# 3065PNPIRA register map
File version: 1.0
Registers are 32-bit, access per field, reset 0x0 unless marked. A register's access mark holds for its fields unless they carry their own. Offsets are from the block's base; [hi:lo] are bit positions; {n}, {i} and the like mark numbered series.

## SYSCTRL1 — SYSCTRL1 peripheral interface
Base 0x10100000
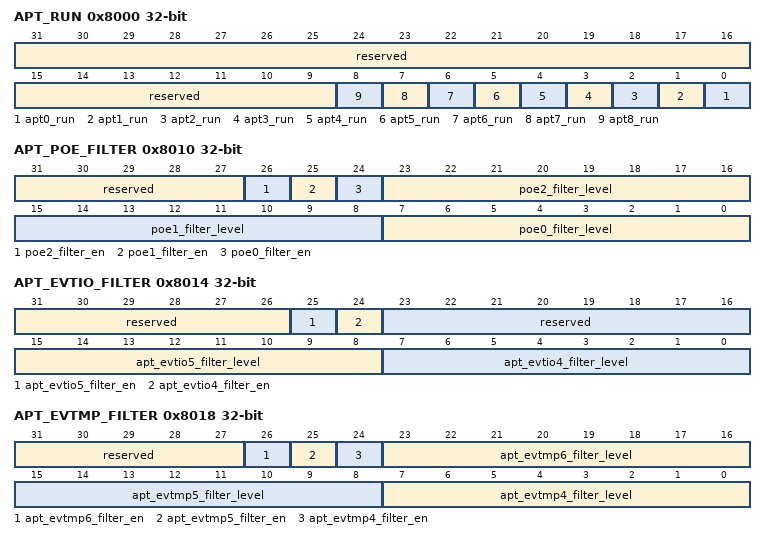
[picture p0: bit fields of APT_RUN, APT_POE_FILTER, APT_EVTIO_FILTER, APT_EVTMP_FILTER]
0x8000 APT_RUN — APT_RUN为APT使能控制寄存器。
  [31:9] reserved ro — 保留。
  [n] apt{n}_run rw (n=0..8) — APT{n}使能。 0：不使能； 1：使能。
0x8010 APT_POE_FILTER — APT_POE_FILTER为APT POE滤波控制寄存器。
  [31:27] reserved ro — 保留。
  [26] poe2_filter_en rw — POE2 FILTER使能。 0：不使能； 1：使能。
  [25] poe1_filter_en rw — POE1 FILTER使能。 0：不使能； 1：使能。
  [24] poe0_filter_en rw — POE0 FILTER使能。 0：不使能； 1：使能。
  [23:16] poe2_filter_level rw — POE2 FILTER周期数（系统总线时钟）。
  [15:8] poe1_filter_level rw — POE1 FILTER周期数（系统总线时钟）。
  [7:0] poe0_filter_level rw — POE0 FILTER周期数（系统总线时钟）。
0x8014 APT_EVTIO_FILTER — APT_EVTIO_FILTER为APT EVTIO滤波控制寄存器。
  [31:26] reserved ro — 保留。
  [25] apt_evtio5_filter_en rw — APT EVTIO5 FILTER使能。 0：不使能； 1：使能。
  [24] apt_evtio4_filter_en rw — APT EVTIO4 FILTER使能。 0：不使能； 1：使能。
  [23:16] reserved ro — 保留。
  [15:8] apt_evtio5_filter_level rw — APT EVTIO5 FILTER周期数（系统总线时钟）。
  [7:0] apt_evtio4_filter_level rw — APT EVTIO4 FILTER周期数（系统总线时钟）。
0x8018 APT_EVTMP_FILTER — APT_EVTMP_FILTER为APT EVTMP滤波控制寄存器。
  [31:27] reserved ro — 保留。
  [26] apt_evtmp6_filter_en rw — APT EVTMP6 FILTER使能。 0：不使能； 1：使能。
  [25] apt_evtmp5_filter_en rw — APT EVTMP5 FILTER使能。 0：不使能； 1：使能。
  [24] apt_evtmp4_filter_en rw — APT EVTMP4 FILTER使能。 0：不使能； 1：使能。
  [23:16] apt_evtmp6_filter_level rw — APT EVTMP6 FILTER周期数（系统总线时钟）。
  [15:8] apt_evtmp5_filter_level rw — APT EVTMP5 FILTER周期数（系统总线时钟）。
  [7:0] apt_evtmp4_filter_level rw — APT EVTMP4 FILTER周期数（系统总线时钟）。
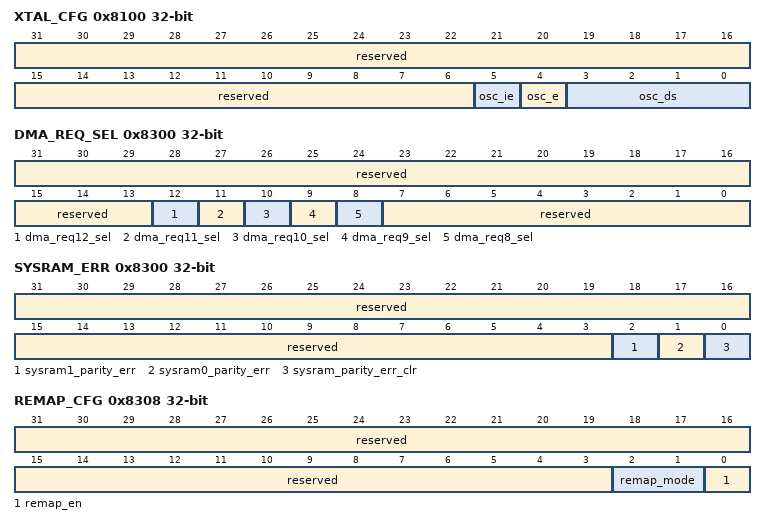
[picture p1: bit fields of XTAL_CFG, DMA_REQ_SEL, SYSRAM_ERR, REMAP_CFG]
0x8100 XTAL_CFG — XTAL_CFG为晶体IO控制寄存器。
  [31:6] reserved ro — 保留。
  [5] osc_ie rw — 晶体IO时钟输入使能。 0：不使能； 1：使能。
  [4] osc_e rw — 晶体IO谐振buf使能。 0：不使能； 1：使能。
  [3:0] osc_ds rw — 晶体IO驱动能力配置。 配置值越大，驱动能力越大。
0x8300 DMA_REQ_SEL — DMA_REQ_SEL为DMA请求线源选择寄存器。
  [31:13] reserved ro — 保留。
  [12] dma_req12_sel rw — DMA请求线12源选择。 0：CAPM0； 1：ADC2。
  [11] dma_req11_sel rw — DMA请求线11源选择。 0：SPI1_TX； 1：UART4_TX。
  [10] dma_req10_sel rw — DMA请求线10源选择。 0：SPI1_RX； 1：UART4_RX。
  [9] dma_req9_sel rw — DMA请求线9源选择。 0：SPI0_TX； 1：UART3_TX。
  [8] dma_req8_sel rw — DMA请求线8源选择。 0：SPI0_RX； 1：UART3_RX。
  [7:0] reserved ro — 保留。
0x8300 SYSRAM_ERR — SYSRAM_ERR为SYSRAM奇偶校验状态寄存器。
  [31:3] reserved ro — 保留。
  [2] sysram1_parity_err ro — SYSRAM奇偶校验错误状态。 0：无错误； 1：有错误。
  [1] sysram0_parity_err ro — SYSRAM奇偶校验错误状态。 0：无错误； 1：有错误。
  [0] sysram_parity_err_clr wo — SYSRAM奇偶校验错误状态清除。 向该位域执行写动作，会清除SYSRAM奇偶校验错误状态。
0x8308 REMAP_CFG — REMAP_CFG为系统地址空间重映射配置寄存器。 该寄存器受写保护控制，由寄存器SC_LOCKEN[sc_cfg_lock]决定。只有写使能时，对此寄存器的写操作才有效。
  [31:3] reserved ro — 保留。
  [2:1] remap_mode rw — 系统地址空间重映射模式。 00：4KB交换。系统访问0x0300_0000～0x0300_0FFF映射到FLASH main区域地址0x0300_1000~0x300_1FFF，系统访问0x0300_1000~0x0300_1FFF映射到FLASH main区域地址0x0300_0000~0x300_0FFF； 01：8KB交换。系统访问0x0300_0000~0x0300_1FFF映射到FLASH main区域地址0x0300_1000~0x300_3FFF，系统访问0x0300_1000~0x0300_3FFF映射到FLASH main区域地址0x0300_0000~0x300_1FFF； 10：128KB交换。系统访问0x0300_0000~0x0301_FFFF映射到FLASH main区域地址0x0302_0000~0x303_FFFF，系统访问0x0302_0000~0x0303_FFFF映射到FLASH main区域地址0x0300_0000~0x301_FFFF； 11：256KB交换。系统访问0x0300_0000~0x0303_FFFF映射到FLASH main区域地址0x0304_0000~0x307_FFFF，系统访问0x0304_0000~0x0307_FFFF映射到FLASH main区域地址0x0300_0000~0x303_FFFF的。
  [0] remap_en rw — 系统地址空间重映射使能。 0：不使能； 1：使能。 请先配置REMAP_CFG[remap_mode]，再配置remap_en使能地址重映射，在使能后紧随4条FENCE指令，以清空CPU流水线，完成地址重映射。
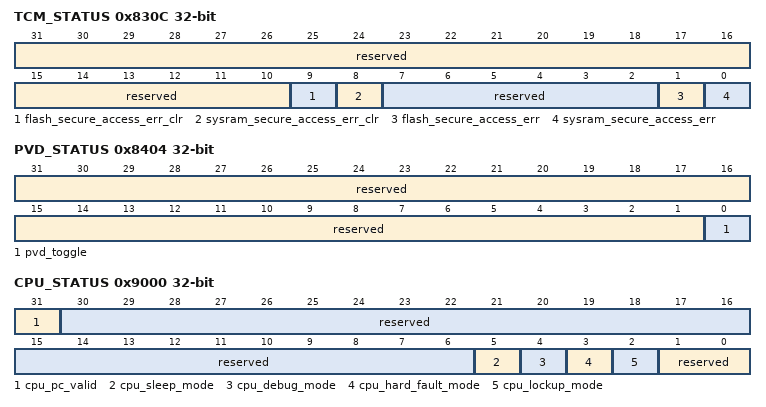
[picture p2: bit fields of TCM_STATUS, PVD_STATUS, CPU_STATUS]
0x830C TCM_STATUS — TCM_STATUS为TCM访问状态寄存器。
  [31:10] reserved ro — 保留。
  [9] flash_secure_access_err_clr wo — FLASH DTCM安全访问状态。 向该位域写1，会清除FLASH DTCM安全访问错误状态。
  [8] sysram_secure_access_err_clr wo — SYSRAM DTCM安全访问状态。 向该位域写1，会清除SYSRAM DTCM安全访问错误状态。
  [7:2] reserved ro — 保留。
  [1] flash_secure_access_err ro — FLASH DTCM安全访问状态。 0：无非法访问； 1：有非法访问。
  [0] sysram_secure_access_err ro — SYSRAM DTCM安全访问状态。 0：无非法访问； 1：有非法访问。
0x8404 PVD_STATUS ro — PVD_STATUS为PVD状态寄存器。
  [31:1] reserved — 保留。
  [0] pvd_toggle — PVD触发标识。
0x9000 CPU_STATUS ro — CPU_STATUS为CPU状态寄存器。
  [31] cpu_pc_valid — CPU PC值有效状态。 0：PC值无效； 1：PC值有效。
  [30:6] reserved — 保留。
  [5] cpu_sleep_mode — CPU SLEEP状态。 0：非sleep状态； 1：sleep状态。
  [4] cpu_debug_mode — CPU DEBUG状态。 0：非debug状态； 1：debug状态。
  [3] cpu_hard_fault_mode — CPU HARD FAULT状态。 0：非hard_fault状态； 1：hard_fault状态。
  [2] cpu_lockup_mode — CPU LOCKUP状态。 0：非lockup状态； 1：lockup状态。
  [1:0] reserved — 保留。
